# IWRL6432 register map
File version: 1.0
CPU: CM4 1.0, other endian, MPU, FPU, 3 interrupt priority bits
Registers are 32-bit, read-write, reset 0x0 unless marked. A register's access mark holds for its fields unless they carry their own. Offsets are from the block's base; [hi:lo] are bit positions; {n}, {i} and the like mark numbered series.

## APP_CANCFG
Base 0x53F7F800
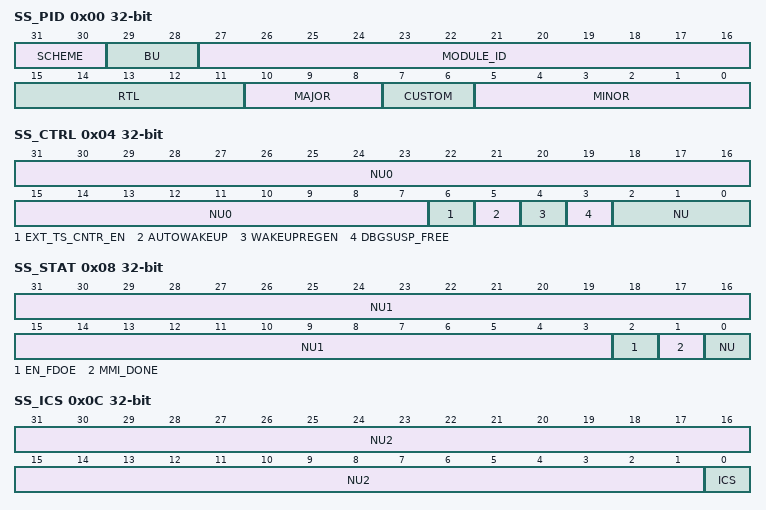
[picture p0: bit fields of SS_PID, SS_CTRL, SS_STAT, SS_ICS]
0x00 SS_PID
  [31:30] SCHEME — [31:30] PID register scheme
  [29:28] BU — [29:28] Business Unit: 10 = Processors
  [27:16] MODULE_ID — [27:16] Module ID
  [15:11] RTL — [15:11] RTL revision. Will vary depending on release.
  [10:8] MAJOR — [10:8] Major revision
  [7:6] CUSTOM — [7:6] Custom
  [5:0] MINOR — [5:0] Minor revision
0x04 SS_CTRL
  [31:7] NU0 — [31:7] Reserved
  [6] EXT_TS_CNTR_EN — [6:6] External TimeStamp Counter Enable
  [5] AUTOWAKEUP — [5:5] Automatic Wakeup Enable
  [4] WAKEUPREGEN — [4:4] Wakeup Request Enable
  [3] DBGSUSP_FREE — [3:3] 0-Honor Debug Suspend, 1-Disregard debug suspend
  [2:0] NU — [2:0] Reserved
0x08 SS_STAT
  [31:3] NU1 — [31:3] Reserved
  [2] EN_FDOE — [2:2] Reflects the value of mcanss_enable_fdoe configuration port x=mcanss_enable_fdoe
  [1] MMI_DONE — [1:1] 0:Memory Initialization is in progress, 1:Memory Intialization Done
  [0] NU — [0:0] Reserved
0x0C SS_ICS
  [31:1] NU2 — [31:1] Reserved
  [0] ICS — [0:0] This bit contains the External TimeStamp Counter Overflow Interrupt status. Write '1' to clear bits. (ICS - Interrupt Clear Shadow Register)
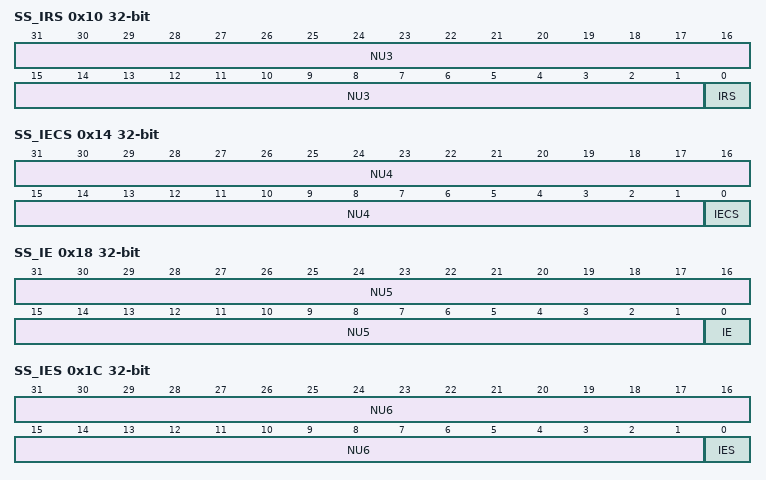
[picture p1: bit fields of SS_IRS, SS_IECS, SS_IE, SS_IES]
0x10 SS_IRS
  [31:1] NU3 — [31:1] Reserved
  [0] IRS — [0:0] External TimeStamp Counter Overflow Interrupt status. Read raw interrupt status. (IRS - Interrupt Raw Status Register)
0x14 SS_IECS
  [31:1] NU4 — [31:1] Reserved
  [0] IECS — [0:0] External TimeStamp Counter Overflow Interrupt. Write '1' to clear bits. (IECS - Interrupt Enable Clear Shadow Register)
0x18 SS_IE
  [31:1] NU5 — [31:1] Reserved
  [0] IE — [0:0] External TimeStamp Counter Overflow Interrupt. Write '1' to set interrupt enable. Read returns interrupt enable. (IE - Interrupt Enable Register)
0x1C SS_IES
  [31:1] NU6 — [31:1] Reserved
  [0] IES — [0:0] External TimeStamp Counter Overflow Interrupt. Read Enabled Interrupts. (IES - Interrupt Enable Status)
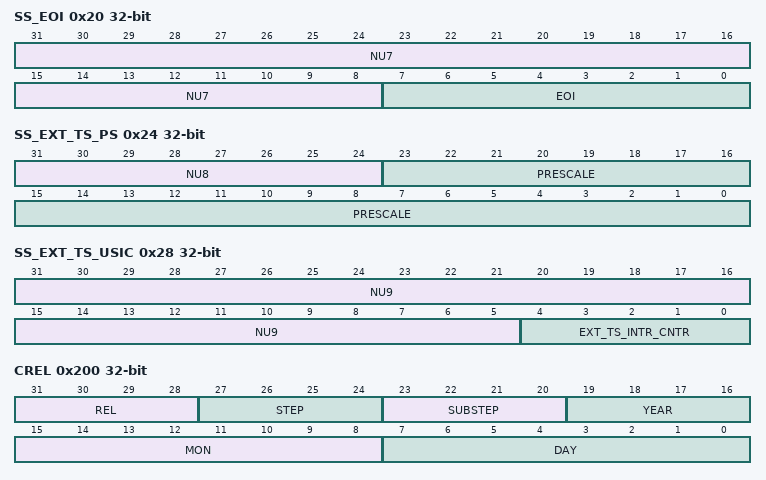
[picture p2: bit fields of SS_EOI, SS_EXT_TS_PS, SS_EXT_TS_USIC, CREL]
0x20 SS_EOI
  [31:8] NU7 — [31:8] Reserved
  [7:0] EOI — [7:0] Write with bit position of targeted interrupt. (E.g. Ext TS is bit 0). Upon write, level interrupt will clear and if unserviced interrupt counter > 1 will issue another pulse interrupt. Field values: ext_ts_eoi(0): EOI value for External TS interrupt mcan_0_eoi(1): EOI value for mcan[0] interrupt mcan_1_eoi(2): EOI value for mcan[1] interrupt (EOI - End Of Interrupt)
0x24 SS_EXT_TS_PS
  [31:24] NU8 — [31:24] Reserved
  [23:0] PRESCALE — [23:0] External Timestamp Prescaler reload value. External Timestamp count rate is host clock rate divided by this value with one exception: a value of 0 has the same effect as 1 .
0x28 SS_EXT_TS_USIC
  [31:5] NU9 — [31:5] Reserved
  [4:0] EXT_TS_INTR_CNTR — [4:0] Number of unserviced rollover interrupts. If >1 an EOI write will issue another pulse interrupt (EXT_TS_USIC - External TImeStamp Unserviced Interrupts Counter)
0x200 CREL
  [31:28] REL — [31:28] Core Release
  [27:24] STEP — [27:24] Step of Core Release
  [23:20] SUBSTEP — [23:20] Sub-Step of Core Release
  [19:16] YEAR — [19:16] Time Stamp Year
  [15:8] MON — [15:8] Time Stamp Month
  [7:0] DAY — [7:0] Time Stamp Day
0x204 ENDN
  [31:0] ETV — [31:0] Endianess test value
0x208 CUST
  [31:0] CUST — [31:0] Custom
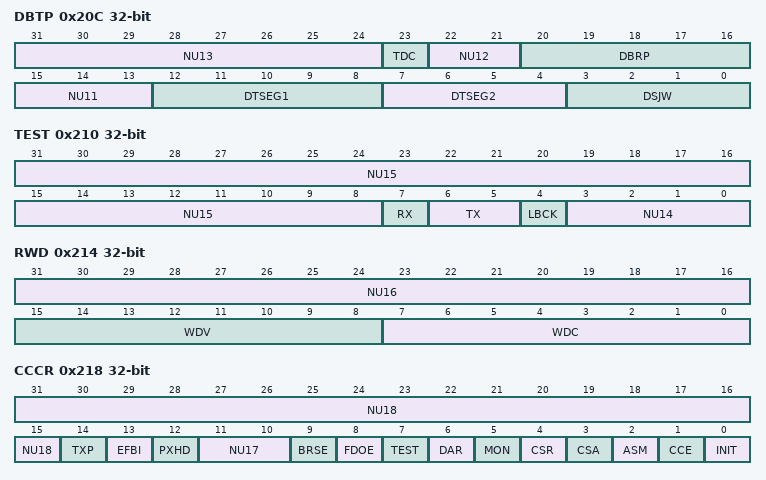
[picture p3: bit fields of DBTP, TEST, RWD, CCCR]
0x20C DBTP
  [31:24] NU13 — [31:24] Reserved
  [23] TDC — [23:23] Transmitter Delay Compensation
  [22:21] NU12 — [22:21] Reserved
  [20:16] DBRP — [20:16] Data Baud Rate Prescaler
  [15:13] NU11 — [15:13] Reserved
  [12:8] DTSEG1 — [12:8] Data time segment before smaple point
  [7:4] DTSEG2 — [7:4] Data time segment after sample point
  [3:0] DSJW — [3:0] Data resynchronization Jump Width
0x210 TEST
  [31:8] NU15 — [31:8] Reserved
  [7] RX — [7:7] Receive Pin
  [6:5] TX — [6:5] Control of Transmit Pin
  [4] LBCK — [4:4] Loop Back Mode
  [3:0] NU14 — [3:0] Reserved
0x214 RWD
  [31:16] NU16 — [31:16] Reserved
  [15:8] WDV — [15:8] Watchdog Value
  [7:0] WDC — [7:0] Watchdog Counter Value
0x218 CCCR
  [31:15] NU18 — [31:15] Reserved
  [14] TXP — [14:14] Transmit Pause
  [13] EFBI — [13:13] Edge Filtering durign Bus Integration
  [12] PXHD — [12:12] Protocol Exception Handling Disable
  [11:10] NU17 — [11:10] Reserved
  [9] BRSE — [9:9] Bit Rate Switch Enable
  [8] FDOE — [8:8] FD Operation Enable
  [7] TEST — [7:7] Test Mode enable
  [6] DAR — [6:6] Disable Automatic Regransmission
  [5] MON — [5:5] Bus Monitoring Mode
  [4] CSR — [4:4] Clock Stop Request
  [3] CSA — [3:3] Clock Stop Acknowledge
  [2] ASM — [2:2] Restriced Operation Mode
  [1] CCE — [1:1] Configuration Change Enable
  [0] INIT — [0:0] Initialization
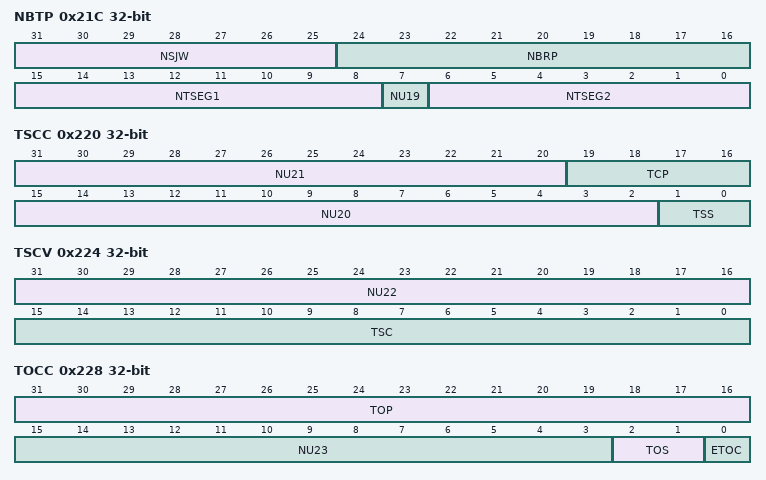
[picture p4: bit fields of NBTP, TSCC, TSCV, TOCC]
0x21C NBTP
  [31:25] NSJW — [31:25] Nominal Resynchronization Jump Width
  [24:16] NBRP — [24:16] Nominal Baud Rate Prescaler
  [15:8] NTSEG1 — [15:8] Nominal Time segment before sample point
  [7] NU19 — [7:7] Reserved
  [6:0] NTSEG2 — [6:0] Nominal Time segment after sample point
0x220 TSCC
  [31:20] NU21 — [31:20] Reserved
  [19:16] TCP — [19:16] Timestamp Counter Prescaler
  [15:2] NU20 — [15:2] Reserved
  [1:0] TSS — [1:0] Timestamp Select
0x224 TSCV
  [31:16] NU22 — [31:16] Reserved
  [15:0] TSC — [15:0] Timestamp Counter
0x228 TOCC
  [31:16] TOP — [31:16] Timeout Period
  [15:3] NU23 — [15:3] Reserved
  [2:1] TOS — [2:1] Timeout Select
  [0] ETOC — [0:0] Enable Timeout Counter
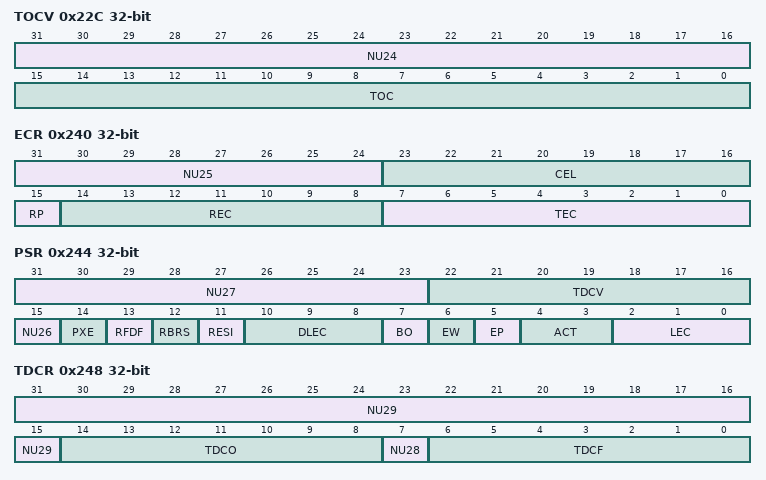
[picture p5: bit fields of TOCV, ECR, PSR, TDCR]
0x22C TOCV
  [31:16] NU24 — [31:16] Reserved
  [15:0] TOC — [15:0] Timeout Counter
{0x230+4i} RES{i:02} (i=0..3)
  [31:0] RES{i:02} — [31:0] Reserved
0x240 ECR
  [31:24] NU25 — [31:24] Reserved
  [23:16] CEL — [23:16] CAN Error Logging
  [15] RP — [15:15] Recieve Error Passive
  [14:8] REC — [14:8] Recieve Error Counter
  [7:0] TEC — [7:0] Transmit Error Counter
0x244 PSR
  [31:23] NU27 — [31:23] Reserved
  [22:16] TDCV — [22:16] Transmitter Delay Compensation Value
  [15] NU26 — [15:15] Reserved
  [14] PXE — [14:14] Protocol Exception Event
  [13] RFDF — [13:13] Recieved a CAN FD Message
  [12] RBRS — [12:12] BRS flag of last recieved CAN FD Message
  [11] RESI — [11:11] ESI flag of last recieved CAN FD Message
  [10:8] DLEC — [10:8] Data Phase Last Error Code
  [7] BO — [7:7] Bus_Off status
  [6] EW — [6:6] Warning Status
  [5] EP — [5:5] Error Passive
  [4:3] ACT — [4:3] Activity
  [2:0] LEC — [2:0] Last Error Code
0x248 TDCR
  [31:15] NU29 — [31:15] Reserved
  [14:8] TDCO — [14:8] Transmitter Delay Compensation Offset
  [7] NU28 — [7:7] Reserved
  [6:0] TDCF — [6:0] Transmitter Delay Compensation Filter Window Length
0x24C RES04
  [31:0] RES04 — [31:0] Reserved
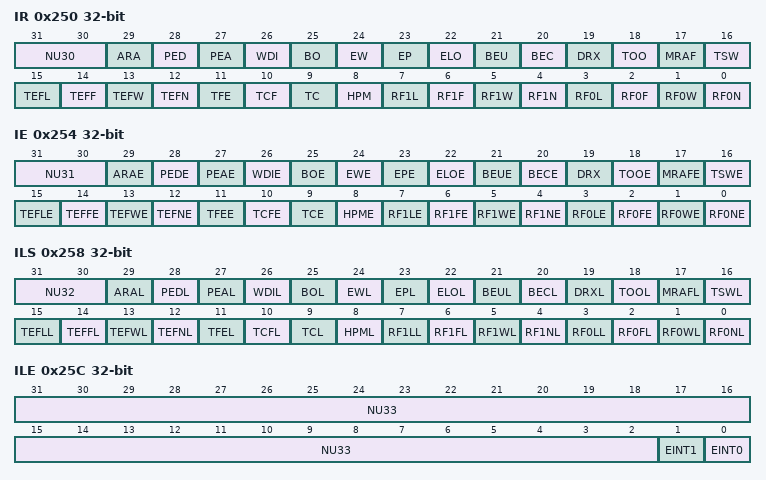
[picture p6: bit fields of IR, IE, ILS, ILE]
0x250 IR
  [31:30] NU30 — [31:30] Reserved
  [29] ARA — [29:29] Access to Reserved Address
  [28] PED — [28:28] Protocol Error in data Phase
  [27] PEA — [27:27] Protocol Error in Arbitration Phase
  [26] WDI — [26:26] Watchdog Interrupt
  [25] BO — [25:25] Bus_Off Status
  [24] EW — [24:24] Warning Status
  [23] EP — [23:23] Error Passive
  [22] ELO — [22:22] Error Logging Overflow
  [21] BEU — [21:21] Bit Error Uncorrected
  [20] BEC — [20:20] Bit Error Corrected
  [19] DRX — [19:19] Message stored to Dedicated Rx Buffer
  [18] TOO — [18:18] Timeout Occurred
  [17] MRAF — [17:17] Message RAM Access Failure
  [16] TSW — [16:16] Timestamp Wraparound
  [15] TEFL — [15:15] Tx Event FIFO Element Lost
  [14] TEFF — [14:14] Tx Event FIFO Full
  [13] TEFW — [13:13] Tx Event FIFO Watermark Reached
  [12] TEFN — [12:12] Tx Event FIFO New Entry
  [11] TFE — [11:11] Tx FIFO Empty
  [10] TCF — [10:10] Transmission Cancellation Finished
  [9] TC — [9:9] Transmission Complete
  [8] HPM — [8:8] High Priority Message
  [7] RF1L — [7:7] Rx FIFO 1 Message Lost
  [6] RF1F — [6:6] Rx FIFO 1 Full
  [5] RF1W — [5:5] Rx FIFO 1 Watermark Reached
  [4] RF1N — [4:4] Rx FIFO 1 New Message
  [3] RF0L — [3:3] Rx FIFO 0 Message Lost
  [2] RF0F — [2:2] Rx FIFO 0 Full
  [1] RF0W — [1:1] Rx FIFO 0 Watermark Reached
  [0] RF0N — [0:0] Rx FIFO 0 New Message
0x254 IE
  [31:30] NU31 — [31:30] Reserved
  [29] ARAE — [29:29] Accees to Reserve Address Interrupt Enable
  [28] PEDE — [28:28] Protocol Error in Data Phase Interrupt Enable
  [27] PEAE — [27:27] Protocol Error in Arbitration Phase Interrupt Enable
  [26] WDIE — [26:26] Watchdog Interrupt Enable
  [25] BOE — [25:25] Bus_Off Status Interrupt Enable
  [24] EWE — [24:24] Warning Status Interrupt Enable
  [23] EPE — [23:23] Error Passive Interrupt Enable
  [22] ELOE — [22:22] Error Logging Overflow Interrupt Enable
  [21] BEUE — [21:21] Bit Error Uncorrected Interrupt Enable
  [20] BECE — [20:20] Bit Error Corrected Interrupt Enable
  [19] DRX — [19:19] Message stored to Dedicated Rx Buffer Interrupt Enable
  [18] TOOE — [18:18] Timeout Occurred Interrupt Enable
  [17] MRAFE — [17:17] Message RAM Access Failure Interrupt Enable
  [16] TSWE — [16:16] Timestamp Wraparound Interrupt Enable
  [15] TEFLE — [15:15] Tx Event FIFO Event Lost Interrupt Enable
  [14] TEFFE — [14:14] Tx Event FIFO Full Interrupt Enable
  [13] TEFWE — [13:13] Tx Event FIFO Watermark Reached Interrupt enable
  [12] TEFNE — [12:12] Tx Event FIFO New Entry Interrupt Enable
  [11] TFEE — [11:11] Tx FIFO Empty Interrupt Enable
  [10] TCFE — [10:10] Transmission Cancellation Finishied Interrupt Enable
  [9] TCE — [9:9] Transmission Completed Interrupt Enable
  [8] HPME — [8:8] High Priority message Interrupt Enable
  [7] RF1LE — [7:7] rx FIFO 1 Message Lost Interrupt Enable
  [6] RF1FE — [6:6] Rx FIFO 1 Full Interrupt Enable
  [5] RF1WE — [5:5] Rx FIFO 1 Watermark Reached Interrupt Enable
  [4] RF1NE — [4:4] Rx FIFO 1 New Message Interrupt Enable
  [3] RF0LE — [3:3] Rx FIFO 0 Message Lost Interrupt Enable
  [2] RF0FE — [2:2] Rx FIFO 0 Full Interrupt Enable
  [1] RF0WE — [1:1] Rx FIFO 0 Watermark Reached Interrupt Enable
  [0] RF0NE — [0:0] Rx FIFO 0 New Message Interrupt Enable
0x258 ILS
  [31:30] NU32 — [31:30] Reserved
  [29] ARAL — [29:29] Accees to Reserve Address Interrupt Line
  [28] PEDL — [28:28] Protocol Error in Data Phase Interrupt Line
  [27] PEAL — [27:27] Protocol Error in Arbitration Phase Interrupt Line
  [26] WDIL — [26:26] Watchdog Interrupt Line
  [25] BOL — [25:25] Bus_Off Status Interrupt Line
  [24] EWL — [24:24] Warning Status Interrupt Line
  [23] EPL — [23:23] Error Passive Interrupt Line
  [22] ELOL — [22:22] Error Logging Overflow Interrupt Line
  [21] BEUL — [21:21] Bit Error Uncorrected Interrupt Line
  [20] BECL — [20:20] Bit Error Corrected Interrupt Line
  [19] DRXL — [19:19] Message stored to Dedicated Rx Buffer Interrupt Line
  [18] TOOL — [18:18] Timeout Occurred Interrupt Line
  [17] MRAFL — [17:17] Message RAM Access Failure Interrupt Line
  [16] TSWL — [16:16] Timestamp Wraparound Interrupt Line
  [15] TEFLL — [15:15] Tx Event FIFO Event Lost Interrupt Line
  [14] TEFFL — [14:14] Tx Event FIFO Full Interrupt Line
  [13] TEFWL — [13:13] Tx Event FIFO Watermark Reached Interrupt Line
  [12] TEFNL — [12:12] Tx Event FIFO New Entry Interrupt Line
  [11] TFEL — [11:11] Tx FIFO Empty Interrupt Line
  [10] TCFL — [10:10] Transmission Cancellation Finishied Interrupt Line
  [9] TCL — [9:9] Transmission Completed Interrupt Line
  [8] HPML — [8:8] High Priority message Interrupt Line
  [7] RF1LL — [7:7] rx FIFO 1 Message Lost Interrupt Line
  [6] RF1FL — [6:6] Rx FIFO 1 Full Interrupt Line
  [5] RF1WL — [5:5] Rx FIFO 1 Watermark Reached Interrupt Line
  [4] RF1NL — [4:4] Rx FIFO 1 New Message Interrupt Line
  [3] RF0LL — [3:3] Rx FIFO 0 Message Lost Interrupt Line
  [2] RF0FL — [2:2] Rx FIFO 0 Full Interrupt Line
  [1] RF0WL — [1:1] Rx FIFO 0 Watermark Reached Interrupt Line
  [0] RF0NL — [0:0] Rx FIFO 0 New Message Interrupt Line
0x25C ILE
  [31:2] NU33 — [31:2] Reserved
  [1] EINT1 — [1:1] Enable Interrupt Line 1
  [0] EINT0 — [0:0] Enable Interrupt Line 0
{0x24C+4i} RES{i:02} (i=5..12)
  [31:0] RES{i:02} — [31:0] Reserved
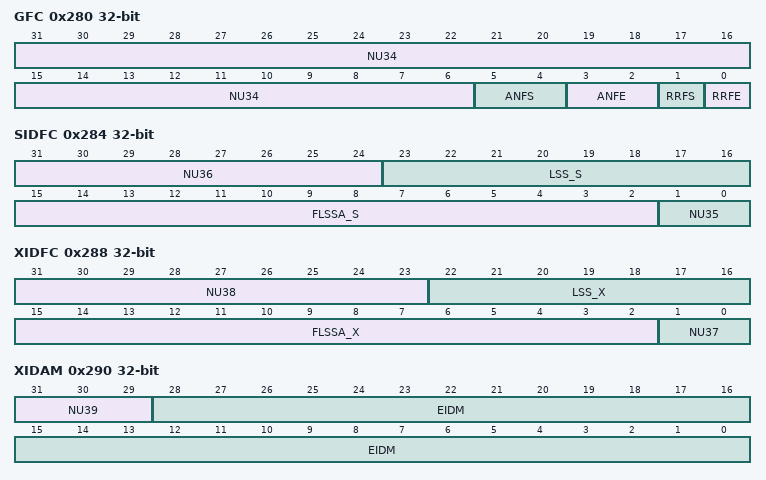
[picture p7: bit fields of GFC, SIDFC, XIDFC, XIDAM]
0x280 GFC
  [31:6] NU34 — [31:6] Reserved
  [5:4] ANFS — [5:4] Accept Non-matching Frames Standard
  [3:2] ANFE — [3:2] Accept Non-matching Frames Extended
  [1] RRFS — [1:1] reject Remote Frames Standard
  [0] RRFE — [0:0] reject Remote Frames Extended
0x284 SIDFC
  [31:24] NU36 — [31:24] Reserved
  [23:16] LSS_S — [23:16] List Size Standard
  [15:2] FLSSA_S — [15:2] Filter List Standard Start Address
  [1:0] NU35 — [1:0] Reserved
0x288 XIDFC
  [31:23] NU38 — [31:23] Reserved
  [22:16] LSS_X — [22:16] List Size Standard
  [15:2] FLSSA_X — [15:2] Filter List Standard Start Address
  [1:0] NU37 — [1:0] Reserved
0x28C RES13
  [31:0] RES13 — [31:0] Reserved
0x290 XIDAM
  [31:29] NU39 — [31:29] Reserved
  [28:0] EIDM — [28:0] Extended ID Mask
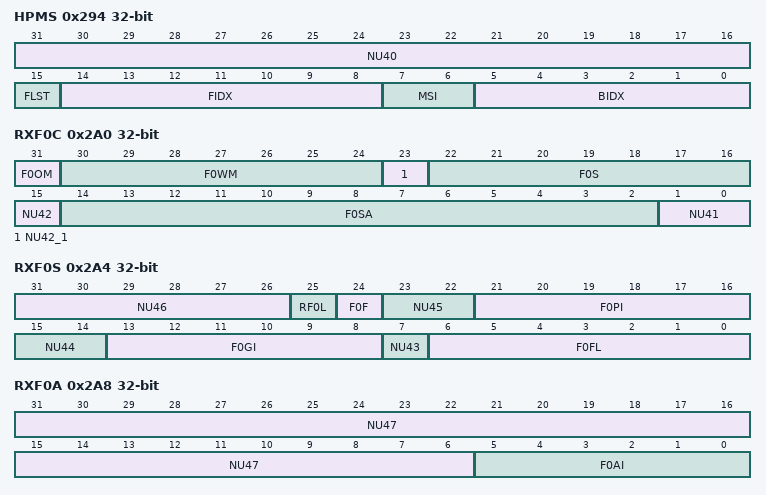
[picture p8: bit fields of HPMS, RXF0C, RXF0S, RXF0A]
0x294 HPMS
  [31:16] NU40 — [31:16] Reserved
  [15] FLST — [15:15] Filter List
  [14:8] FIDX — [14:8] Filter Index
  [7:6] MSI — [7:6] Message Storeage Indicator
  [5:0] BIDX — [5:0] Buffer Index
0x298 NDAT1
  [31:0] ND0_31 — [31:0] New Data 0-31
0x29C NDAT2
  [31:0] ND32_63 — [31:0] New Data 32-63
0x2A0 RXF0C
  [31] F0OM — [31:31] Rx FIFO 0 Operation Mode
  [30:24] F0WM — [30:24] Rx FIFO 0 Watermark
  [23] NU42_1 — [23:23] Reserved
  [22:16] F0S — [22:16] Rx FIFO 0 Size
  [15] NU42 — [15:15] Reserved
  [14:2] F0SA — [14:2] Rx FIFO 0 Start Address
  [1:0] NU41 — [1:0] Reserved
0x2A4 RXF0S
  [31:26] NU46 — [31:26] Reserved
  [25] RF0L — [25:25] Rx FIFO 0 Message Lost
  [24] F0F — [24:24] Rx FIFO 0 Full
  [23:22] NU45 — [23:22] Reserved
  [21:16] F0PI — [21:16] Rx FIFO 0 Put Index
  [15:14] NU44 — [15:14] Reserved
  [13:8] F0GI — [13:8] Rx FIFO 0 Get Index
  [7] NU43 — [7:7] Reserved
  [6:0] F0FL — [6:0] Rx FIFO 0 Fill Level
0x2A8 RXF0A
  [31:6] NU47 — [31:6] Reserved
  [5:0] F0AI — [5:0] Rx FIFO 0 Acknowledge Index
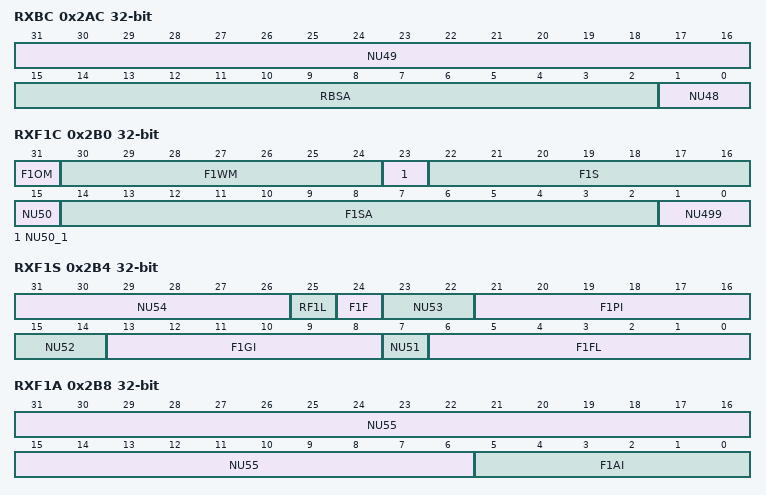
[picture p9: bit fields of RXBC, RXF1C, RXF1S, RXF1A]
0x2AC RXBC
  [31:16] NU49 — [31:16] Reserved
  [15:2] RBSA — [15:2] Rx Buffer Start Address
  [1:0] NU48 — [1:0] Reserved
0x2B0 RXF1C
  [31] F1OM — [31:31] Rx FIFO 0 Operation Mode
  [30:24] F1WM — [30:24] Rx FIFO 0 Watermark
  [23] NU50_1 — [23:23] Reserved
  [22:16] F1S — [22:16] Rx FIFO 0 Size
  [15] NU50 — [15:15] Reserved
  [14:2] F1SA — [14:2] Rx FIFO 0 Start Address
  [1:0] NU499 — [1:0] Reserved
0x2B4 RXF1S
  [31:26] NU54 — [31:26] Reserved
  [25] RF1L — [25:25] Rx FIFO 0 Message Lost
  [24] F1F — [24:24] Rx FIFO 0 Full
  [23:22] NU53 — [23:22] Reserved
  [21:16] F1PI — [21:16] Rx FIFO 0 Put Index
  [15:14] NU52 — [15:14] Reserved
  [13:8] F1GI — [13:8] Rx FIFO 0 Get Index
  [7] NU51 — [7:7] Reserved
  [6:0] F1FL — [6:0] Rx FIFO 0 Fill Level
0x2B8 RXF1A
  [31:6] NU55 — [31:6] Reserved
  [5:0] F1AI — [5:0] Rx FIFO 0 Acknowledge Index
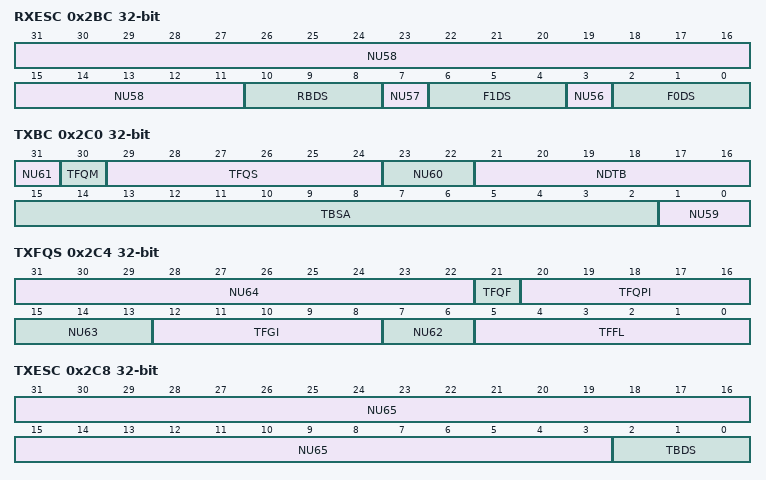
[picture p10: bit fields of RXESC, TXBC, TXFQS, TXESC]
0x2BC RXESC
  [31:11] NU58 — [31:11] Reserved
  [10:8] RBDS — [10:8] Rx Buffer data Field Size
  [7] NU57 — [7:7] Reserved
  [6:4] F1DS — [6:4] Rx FIFO 1 Data Field Size
  [3] NU56 — [3:3] Reserved
  [2:0] F0DS — [2:0] Rx FIFO 0 Data Field Size
0x2C0 TXBC
  [31] NU61 — [31:31] Reserved
  [30] TFQM — [30:30] Tx FIFO/Queue Mode
  [29:24] TFQS — [29:24] Transmit FIFO/Queue Size
  [23:22] NU60 — [23:22] Reserved
  [21:16] NDTB — [21:16] Number of Dedicated Transmit Buffers
  [15:2] TBSA — [15:2] Tx Buffers Start Address
  [1:0] NU59 — [1:0] Reserved
0x2C4 TXFQS
  [31:22] NU64 — [31:22] Reserved
  [21] TFQF — [21:21] Tx FIFO/Queue Full
  [20:16] TFQPI — [20:16] Tx FIFO/Queue Put Index
  [15:13] NU63 — [15:13] Reserved
  [12:8] TFGI — [12:8] Tx Queue Get Index
  [7:6] NU62 — [7:6] Reserved
  [5:0] TFFL — [5:0] Tx FIFO Free Level
0x2C8 TXESC
  [31:3] NU65 — [31:3] Reserved
  [2:0] TBDS — [2:0] Tx Buffer Data Field Size
0x2CC TXBRP
  [31:0] TRP — [31:0] Transmission Request Pending
0x2D0 TXBAR
  [31:0] AR — [31:0] Add request
0x2D4 TXBCR
  [31:0] CR — [31:0] Cancellation Request
0x2D8 TXBTO
  [31:0] TO — [31:0] Transmission Occurred
0x2DC TXBCF
  [31:0] CF — [31:0] Cancellation Finished
0x2E0 TXBTIE
  [31:0] TIE — [31:0] Transmission Interrupt Enable
0x2E4 TXBCIE
  [31:0] CFIE — [31:0] Cancellation Finished Interrupt Enable
0x2E8 RES14
  [31:0] RES14 — [31:0] Reserved
0x2EC RES15
  [31:0] RES15 — [31:0] Reserved
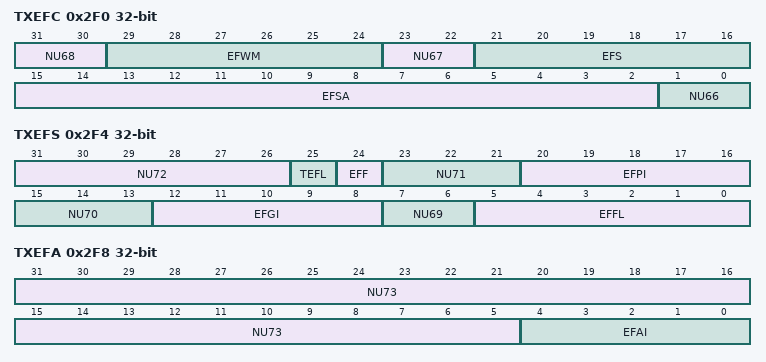
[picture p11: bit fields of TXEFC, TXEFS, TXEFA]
0x2F0 TXEFC
  [31:30] NU68 — [31:30] Reserved
  [29:24] EFWM — [29:24] Event FIFO Watermark
  [23:22] NU67 — [23:22] Reserved
  [21:16] EFS — [21:16] Event FIFO Size
  [15:2] EFSA — [15:2] Event FIFO Start Address
  [1:0] NU66 — [1:0] Reserved
0x2F4 TXEFS
  [31:26] NU72 — [31:26] Reserved
  [25] TEFL — [25:25] Tx Event FIFO Element Lost
  [24] EFF — [24:24] Event FIFO Full
  [23:21] NU71 — [23:21] Reserved
  [20:16] EFPI — [20:16] Event FIFO Put Index
  [15:13] NU70 — [15:13] Reserved
  [12:8] EFGI — [12:8] Event FIFO Get Index
  [7:6] NU69 — [7:6] Reserved
  [5:0] EFFL — [5:0] Event FIFO FIll Level
0x2F8 TXEFA
  [31:5] NU73 — [31:5] Reserved
  [4:0] EFAI — [4:0] Event FIFO Acknowledge Index
0x2FC RES16
  [31:0] RES16 — [31:0] Reserved
